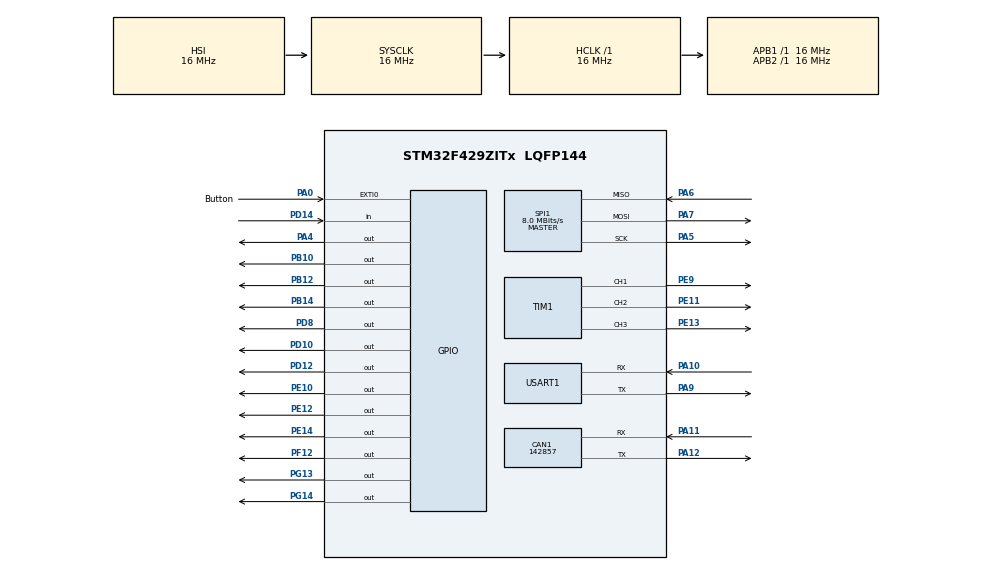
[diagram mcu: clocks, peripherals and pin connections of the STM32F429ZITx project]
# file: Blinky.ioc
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CAN1.BS1=CAN_BS1_4TQ
CAN1.BS2=CAN_BS2_2TQ
CAN1.CalculateBaudRate=142857
CAN1.CalculateTimeBit=7000
CAN1.CalculateTimeQuantum=1000.0
Mcu.Family=STM32F4
Mcu.Name=STM32F429ZITx
Mcu.Package=LQFP144
NVIC.CAN1_RX0_IRQn=true\:0\:0\:false\:false\:true\:true\:true\:true
NVIC.EXTI0_IRQn=true\:0\:0\:false\:false\:true\:true\:true\:true
NVIC.PriorityGroup=NVIC_PRIORITYGROUP_4
NVIC.TIM8_TRG_COM_TIM14_IRQn=true\:0\:0\:false\:false\:true\:true\:true\:true
PA0/WKUP.GPIO_Label=Button
PA0/WKUP.GPIO_ModeDefaultEXTI=GPIO_MODE_IT_RISING
PA0/WKUP.GPIO_PuPd=GPIO_NOPULL
PA0/WKUP.Signal=GPXTI0
PA10.Mode=Asynchronous
PA10.Signal=USART1_RX
PA11.Mode=CAN_Activate
PA11.Signal=CAN1_RX
PA12.Mode=CAN_Activate
PA12.Signal=CAN1_TX
PA4.Signal=GPIO_Output
PA5.Mode=Full_Duplex_Master
PA5.Signal=SPI1_SCK
PA6.Mode=Full_Duplex_Master
PA6.Signal=SPI1_MISO
PA7.Mode=Full_Duplex_Master
PA7.Signal=SPI1_MOSI
PA9.Mode=Asynchronous
PA9.Signal=USART1_TX
PB10.Signal=GPIO_Output
PB12.Signal=GPIO_Output
PB14.Signal=GPIO_Output
PB15.Signal=S_TIM12_CH2
PC14/OSC32_IN.Mode=LSE-External-Oscillator
PC14/OSC32_IN.Signal=RCC_OSC32_IN
PC15/OSC32_OUT.Mode=LSE-External-Oscillator
PC15/OSC32_OUT.Signal=RCC_OSC32_OUT
PD10.Signal=GPIO_Output
PD12.Signal=GPIO_Output
PD14.Signal=GPIO_Input
PD8.Signal=GPIO_Output
PE10.Signal=GPIO_Output
PE11.Signal=S_TIM1_CH2
PE12.Signal=GPIO_Output
PE13.Signal=S_TIM1_CH3
PE14.Signal=GPIO_Output
PE9.Signal=S_TIM1_CH1
PF12.Signal=GPIO_Output
PG13.Signal=GPIO_Output
PG14.Signal=GPIO_Output
PH0/OSC_IN.Mode=HSE-External-Oscillator
PH0/OSC_IN.Signal=RCC_OSC_IN
PH1/OSC_OUT.Mode=HSE-External-Oscillator
PH1/OSC_OUT.Signal=RCC_OSC_OUT
ProjectManager.HeapSize=0x200
ProjectManager.StackSize=0x400
ProjectManager.TargetToolchain=STM32CubeIDE
RCC.AHBFreq_Value=16000000
RCC.APB1Freq_Value=16000000
RCC.APB2Freq_Value=16000000
RCC.CortexFreq_Value=16000000
RCC.HSE_VALUE=25000000
RCC.HSI_VALUE=16000000
RCC.SYSCLKFreq_VALUE=16000000
RCC.VCOOutputFreq_Value=192000000
SH.S_TIM12_CH2.0=TIM12_CH2
SH.S_TIM1_CH1.0=TIM1_CH1,PWM Generation1 CH1
SH.S_TIM1_CH2.0=TIM1_CH2,PWM Generation2 CH2
SH.S_TIM1_CH3.0=TIM1_CH3,PWM Generation3 CH3
SPI1.CalculateBaudRate=8.0 MBits/s
SPI1.DataSize=SPI_DATASIZE_16BIT
SPI1.Direction=SPI_DIRECTION_2LINES
SPI1.Mode=SPI_MODE_MASTER
SPI1.VirtualType=VM_MASTER
TIM1.AutoReloadPreload=TIM_AUTORELOAD_PRELOAD_ENABLE
TIM1.Channel-PWM\ Generation1\ CH1=TIM_CHANNEL_1
TIM1.Channel-PWM\ Generation2\ CH2=TIM_CHANNEL_2
TIM1.Channel-PWM\ Generation3\ CH3=TIM_CHANNEL_3
TIM13.Period=10000-1
TIM13.Prescaler=1600-1
TIM14.Period=10000 - 1
TIM14.Prescaler=1600 -1
USART1.VirtualMode=VM_ASYNC
VP_TIM13_VS_ClockSourceINT.Mode=Enable_Timer
VP_TIM14_VS_ClockSourceINT.Mode=Enable_Timer
VP_TIM1_VS_ClockSourceINT.Mode=Internal
board=custom

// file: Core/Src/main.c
/* USER CODE BEGIN Header */
/**
  ******************************************************************************
  * @file           : main.c
  * @brief          : Main program body
  ******************************************************************************
  * @attention
  *
  * Copyright (c) 2022 STMicroelectronics.
  * All rights reserved.
  *
  * This software is licensed under terms that can be found in the LICENSE file
  * in the root directory of this software component.
  * If no LICENSE file comes with this software, it is provided AS-IS.
  *
  ******************************************************************************
  */
/* USER CODE END Header */
#include "main.h"

 CAN_HandleTypeDef hcan1;

SPI_HandleTypeDef hspi1;

TIM_HandleTypeDef htim1;
TIM_HandleTypeDef htim13;
TIM_HandleTypeDef htim14;

UART_HandleTypeDef huart1;

void SystemClock_Config(void);
static void MX_GPIO_Init(void);
static void MX_TIM1_Init(void);
static void MX_SPI1_Init(void);
static void MX_CAN1_Init(void);
static void MX_USART1_UART_Init(void);
static void MX_TIM14_Init(void);
static void MX_TIM13_Init(void);
/* USER CODE BEGIN PFP */
int flashLEDs = 1;
int buttonVal = 0;
/* USER CODE END PFP */

int main(void)
{

  /* MCU Configuration--------------------------------------------------------*/

  /* Reset of all peripherals, Initializes the Flash interface and the Systick. */
  HAL_Init();

  /* Configure the system clock */
  SystemClock_Config();

  /* Initialize all configured peripherals */
  MX_GPIO_Init();
  MX_TIM1_Init();
  MX_SPI1_Init();
  MX_CAN1_Init();
  MX_USART1_UART_Init();
  MX_TIM14_Init();
  MX_TIM13_Init();
  /* USER CODE BEGIN 2 */
  HAL_UART_Transmit(&huart1, (uint8_t *)"hello\n", strlen("hello\n"), 1000);
  char in[8] = {0};
  /* USER CODE END 2 */

  /* Infinite loop */
  /* USER CODE BEGIN WHILE */
  while (1)
  {
	 if(flashLEDs){
		 HAL_GPIO_TogglePin(GPIOG, GPIO_PIN_13);
		 //HAL_Delay(100);
		 HAL_GPIO_TogglePin(GPIOG, GPIO_PIN_14);
	 }
	 else{
		 HAL_GPIO_WritePin(GPIOG, GPIO_PIN_13, 0);
		 HAL_GPIO_WritePin(GPIOG, GPIO_PIN_14, 0);
	 }
	 buttonVal = HAL_GPIO_ReadPin(GPIOA, GPIO_PIN_0);

	 //HAL_Delay(100);

	 if(HAL_UART_Receive(&huart1, (uint8_t *)in, 8, 1000) == HAL_TIMEOUT){
		 //HAL_UART_Transmit(&huart1, (uint8_t *)"Timeout\n", strlen("Timeout\n") , 10);
	 }
	 else{
		 HAL_UART_Transmit(&huart1, (uint8_t *)in, 8 , 1);
	 }

    /* USER CODE END WHILE */

  }
}

void SystemClock_Config(void)
{
  RCC_OscInitTypeDef RCC_OscInitStruct = {0};
  RCC_ClkInitTypeDef RCC_ClkInitStruct = {0};

  /** Configure the main internal regulator output voltage
  */
  __HAL_RCC_PWR_CLK_ENABLE();
  __HAL_PWR_VOLTAGESCALING_CONFIG(PWR_REGULATOR_VOLTAGE_SCALE3);

  /** Initializes the RCC Oscillators according to the specified parameters
  * in the RCC_OscInitTypeDef structure.
  */
  RCC_OscInitStruct.OscillatorType = RCC_OSCILLATORTYPE_HSI;
  RCC_OscInitStruct.HSIState = RCC_HSI_ON;
  RCC_OscInitStruct.HSICalibrationValue = RCC_HSICALIBRATION_DEFAULT;
  RCC_OscInitStruct.PLL.PLLState = RCC_PLL_NONE;
  if (HAL_RCC_OscConfig(&RCC_OscInitStruct) != HAL_OK)
  {
    Error_Handler();
  }

  /** Initializes the CPU, AHB and APB buses clocks
  */
  RCC_ClkInitStruct.ClockType = RCC_CLOCKTYPE_HCLK|RCC_CLOCKTYPE_SYSCLK
                              |RCC_CLOCKTYPE_PCLK1|RCC_CLOCKTYPE_PCLK2;
  RCC_ClkInitStruct.SYSCLKSource = RCC_SYSCLKSOURCE_HSI;
  RCC_ClkInitStruct.AHBCLKDivider = RCC_SYSCLK_DIV1;
  RCC_ClkInitStruct.APB1CLKDivider = RCC_HCLK_DIV1;
  RCC_ClkInitStruct.APB2CLKDivider = RCC_HCLK_DIV1;

  if (HAL_RCC_ClockConfig(&RCC_ClkInitStruct, FLASH_LATENCY_0) != HAL_OK)
  {
    Error_Handler();
  }
}

static void MX_CAN1_Init(void)
{

  hcan1.Instance = CAN1;
  hcan1.Init.Prescaler = 16;
  hcan1.Init.Mode = CAN_MODE_NORMAL;
  hcan1.Init.SyncJumpWidth = CAN_SJW_1TQ;
  hcan1.Init.TimeSeg1 = CAN_BS1_4TQ;
  hcan1.Init.TimeSeg2 = CAN_BS2_2TQ;
  hcan1.Init.TimeTriggeredMode = DISABLE;
  hcan1.Init.AutoBusOff = DISABLE;
  hcan1.Init.AutoWakeUp = DISABLE;
  hcan1.Init.AutoRetransmission = DISABLE;
  hcan1.Init.ReceiveFifoLocked = DISABLE;
  hcan1.Init.TransmitFifoPriority = DISABLE;
  if (HAL_CAN_Init(&hcan1) != HAL_OK)
  {
    Error_Handler();
  }

}

static void MX_SPI1_Init(void)
{

  /* SPI1 parameter configuration*/
  hspi1.Instance = SPI1;
  hspi1.Init.Mode = SPI_MODE_MASTER;
  hspi1.Init.Direction = SPI_DIRECTION_2LINES;
  hspi1.Init.DataSize = SPI_DATASIZE_16BIT;
  hspi1.Init.CLKPolarity = SPI_POLARITY_LOW;
  hspi1.Init.CLKPhase = SPI_PHASE_1EDGE;
  hspi1.Init.NSS = SPI_NSS_SOFT;
  hspi1.Init.BaudRatePrescaler = SPI_BAUDRATEPRESCALER_2;
  hspi1.Init.FirstBit = SPI_FIRSTBIT_MSB;
  hspi1.Init.TIMode = SPI_TIMODE_DISABLE;
  hspi1.Init.CRCCalculation = SPI_CRCCALCULATION_DISABLE;
  hspi1.Init.CRCPolynomial = 10;
  if (HAL_SPI_Init(&hspi1) != HAL_OK)
  {
    Error_Handler();
  }

}

static void MX_TIM1_Init(void)
{

  TIM_ClockConfigTypeDef sClockSourceConfig = {0};
  TIM_MasterConfigTypeDef sMasterConfig = {0};
  TIM_OC_InitTypeDef sConfigOC = {0};
  TIM_BreakDeadTimeConfigTypeDef sBreakDeadTimeConfig = {0};

  htim1.Instance = TIM1;
  htim1.Init.Prescaler = 0;
  htim1.Init.CounterMode = TIM_COUNTERMODE_UP;
  htim1.Init.Period = 65535;
  htim1.Init.ClockDivision = TIM_CLOCKDIVISION_DIV1;
  htim1.Init.RepetitionCounter = 0;
  htim1.Init.AutoReloadPreload = TIM_AUTORELOAD_PRELOAD_ENABLE;
  if (HAL_TIM_Base_Init(&htim1) != HAL_OK)
  {
    Error_Handler();
  }
  sClockSourceConfig.ClockSource = TIM_CLOCKSOURCE_INTERNAL;
  if (HAL_TIM_ConfigClockSource(&htim1, &sClockSourceConfig) != HAL_OK)
  {
    Error_Handler();
  }
  if (HAL_TIM_PWM_Init(&htim1) != HAL_OK)
  {
    Error_Handler();
  }
  sMasterConfig.MasterOutputTrigger = TIM_TRGO_RESET;
  sMasterConfig.MasterSlaveMode = TIM_MASTERSLAVEMODE_DISABLE;
  if (HAL_TIMEx_MasterConfigSynchronization(&htim1, &sMasterConfig) != HAL_OK)
  {
    Error_Handler();
  }
  sConfigOC.OCMode = TIM_OCMODE_PWM1;
  sConfigOC.Pulse = 0;
  sConfigOC.OCPolarity = TIM_OCPOLARITY_HIGH;
  sConfigOC.OCNPolarity = TIM_OCNPOLARITY_HIGH;
  sConfigOC.OCFastMode = TIM_OCFAST_DISABLE;
  sConfigOC.OCIdleState = TIM_OCIDLESTATE_RESET;
  sConfigOC.OCNIdleState = TIM_OCNIDLESTATE_RESET;
  if (HAL_TIM_PWM_ConfigChannel(&htim1, &sConfigOC, TIM_CHANNEL_1) != HAL_OK)
  {
    Error_Handler();
  }
  if (HAL_TIM_PWM_ConfigChannel(&htim1, &sConfigOC, TIM_CHANNEL_2) != HAL_OK)
  {
    Error_Handler();
  }
  if (HAL_TIM_PWM_ConfigChannel(&htim1, &sConfigOC, TIM_CHANNEL_3) != HAL_OK)
  {
    Error_Handler();
  }
  sBreakDeadTimeConfig.OffStateRunMode = TIM_OSSR_DISABLE;
  sBreakDeadTimeConfig.OffStateIDLEMode = TIM_OSSI_DISABLE;
  sBreakDeadTimeConfig.LockLevel = TIM_LOCKLEVEL_OFF;
  sBreakDeadTimeConfig.DeadTime = 0;
  sBreakDeadTimeConfig.BreakState = TIM_BREAK_DISABLE;
  sBreakDeadTimeConfig.BreakPolarity = TIM_BREAKPOLARITY_HIGH;
  sBreakDeadTimeConfig.AutomaticOutput = TIM_AUTOMATICOUTPUT_DISABLE;
  if (HAL_TIMEx_ConfigBreakDeadTime(&htim1, &sBreakDeadTimeConfig) != HAL_OK)
  {
    Error_Handler();
  }
  HAL_TIM_MspPostInit(&htim1);

}

static void MX_TIM13_Init(void)
{

  htim13.Instance = TIM13;
  htim13.Init.Prescaler = 1600-1;
  htim13.Init.CounterMode = TIM_COUNTERMODE_UP;
  htim13.Init.Period = 10000-1;
  htim13.Init.ClockDivision = TIM_CLOCKDIVISION_DIV1;
  htim13.Init.AutoReloadPreload = TIM_AUTORELOAD_PRELOAD_DISABLE;
  if (HAL_TIM_Base_Init(&htim13) != HAL_OK)
  {
    Error_Handler();
  }

}

static void MX_TIM14_Init(void)
{

  htim14.Instance = TIM14;
  htim14.Init.Prescaler = 1600 -1;
  htim14.Init.CounterMode = TIM_COUNTERMODE_UP;
  htim14.Init.Period = 10000 - 1;
  htim14.Init.ClockDivision = TIM_CLOCKDIVISION_DIV1;
  htim14.Init.AutoReloadPreload = TIM_AUTORELOAD_PRELOAD_DISABLE;
  if (HAL_TIM_Base_Init(&htim14) != HAL_OK)
  {
    Error_Handler();
  }

}

static void MX_USART1_UART_Init(void)
{

  huart1.Instance = USART1;
  huart1.Init.BaudRate = 115200;
  huart1.Init.WordLength = UART_WORDLENGTH_8B;
  huart1.Init.StopBits = UART_STOPBITS_1;
  huart1.Init.Parity = UART_PARITY_NONE;
  huart1.Init.Mode = UART_MODE_TX_RX;
  huart1.Init.HwFlowCtl = UART_HWCONTROL_NONE;
  huart1.Init.OverSampling = UART_OVERSAMPLING_16;
  if (HAL_UART_Init(&huart1) != HAL_OK)
  {
    Error_Handler();
  }

}

static void MX_GPIO_Init(void)
{
  GPIO_InitTypeDef GPIO_InitStruct = {0};

  /* GPIO Ports Clock Enable */
  __HAL_RCC_GPIOC_CLK_ENABLE();
  __HAL_RCC_GPIOH_CLK_ENABLE();
  __HAL_RCC_GPIOA_CLK_ENABLE();
  __HAL_RCC_GPIOF_CLK_ENABLE();
  __HAL_RCC_GPIOE_CLK_ENABLE();
  __HAL_RCC_GPIOB_CLK_ENABLE();
  __HAL_RCC_GPIOD_CLK_ENABLE();
  __HAL_RCC_GPIOG_CLK_ENABLE();

  /*Configure GPIO pin Output Level */
  HAL_GPIO_WritePin(GPIOA, GPIO_PIN_4, GPIO_PIN_RESET);

  /*Configure GPIO pin Output Level */
  HAL_GPIO_WritePin(GPIOF, GPIO_PIN_12, GPIO_PIN_RESET);

  /*Configure GPIO pin Output Level */
  HAL_GPIO_WritePin(GPIOE, GPIO_PIN_10|GPIO_PIN_12|GPIO_PIN_14, GPIO_PIN_RESET);

  /*Configure GPIO pin Output Level */
  HAL_GPIO_WritePin(GPIOB, GPIO_PIN_10|GPIO_PIN_12|GPIO_PIN_14, GPIO_PIN_RESET);

  /*Configure GPIO pin Output Level */
  HAL_GPIO_WritePin(GPIOD, GPIO_PIN_8|GPIO_PIN_10|GPIO_PIN_12, GPIO_PIN_RESET);

  /*Configure GPIO pin Output Level */
  HAL_GPIO_WritePin(GPIOG, GPIO_PIN_13|GPIO_PIN_14, GPIO_PIN_RESET);

  /*Configure GPIO pin : Button_Pin */
  GPIO_InitStruct.Pin = Button_Pin;
  GPIO_InitStruct.Mode = GPIO_MODE_IT_RISING;
  GPIO_InitStruct.Pull = GPIO_NOPULL;
  HAL_GPIO_Init(Button_GPIO_Port, &GPIO_InitStruct);

  /*Configure GPIO pin : PA4 */
  GPIO_InitStruct.Pin = GPIO_PIN_4;
  GPIO_InitStruct.Mode = GPIO_MODE_OUTPUT_PP;
  GPIO_InitStruct.Pull = GPIO_NOPULL;
  GPIO_InitStruct.Speed = GPIO_SPEED_FREQ_LOW;
  HAL_GPIO_Init(GPIOA, &GPIO_InitStruct);

  /*Configure GPIO pin : PF12 */
  GPIO_InitStruct.Pin = GPIO_PIN_12;
  GPIO_InitStruct.Mode = GPIO_MODE_OUTPUT_PP;
  GPIO_InitStruct.Pull = GPIO_NOPULL;
  GPIO_InitStruct.Speed = GPIO_SPEED_FREQ_LOW;
  HAL_GPIO_Init(GPIOF, &GPIO_InitStruct);

  /*Configure GPIO pins : PE10 PE12 PE14 */
  GPIO_InitStruct.Pin = GPIO_PIN_10|GPIO_PIN_12|GPIO_PIN_14;
  GPIO_InitStruct.Mode = GPIO_MODE_OUTPUT_PP;
  GPIO_InitStruct.Pull = GPIO_NOPULL;
  GPIO_InitStruct.Speed = GPIO_SPEED_FREQ_LOW;
  HAL_GPIO_Init(GPIOE, &GPIO_InitStruct);

  /*Configure GPIO pins : PB10 PB12 PB14 */
  GPIO_InitStruct.Pin = GPIO_PIN_10|GPIO_PIN_12|GPIO_PIN_14;
  GPIO_InitStruct.Mode = GPIO_MODE_OUTPUT_PP;
  GPIO_InitStruct.Pull = GPIO_NOPULL;
  GPIO_InitStruct.Speed = GPIO_SPEED_FREQ_LOW;
  HAL_GPIO_Init(GPIOB, &GPIO_InitStruct);

  /*Configure GPIO pin : PB15 */
  GPIO_InitStruct.Pin = GPIO_PIN_15;
  GPIO_InitStruct.Mode = GPIO_MODE_AF_PP;
  GPIO_InitStruct.Pull = GPIO_NOPULL;
  GPIO_InitStruct.Speed = GPIO_SPEED_FREQ_LOW;
  GPIO_InitStruct.Alternate = GPIO_AF9_TIM12;
  HAL_GPIO_Init(GPIOB, &GPIO_InitStruct);

  /*Configure GPIO pins : PD8 PD10 PD12 */
  GPIO_InitStruct.Pin = GPIO_PIN_8|GPIO_PIN_10|GPIO_PIN_12;
  GPIO_InitStruct.Mode = GPIO_MODE_OUTPUT_PP;
  GPIO_InitStruct.Pull = GPIO_NOPULL;
  GPIO_InitStruct.Speed = GPIO_SPEED_FREQ_LOW;
  HAL_GPIO_Init(GPIOD, &GPIO_InitStruct);

  /*Configure GPIO pin : PD14 */
  GPIO_InitStruct.Pin = GPIO_PIN_14;
  GPIO_InitStruct.Mode = GPIO_MODE_INPUT;
  GPIO_InitStruct.Pull = GPIO_NOPULL;
  HAL_GPIO_Init(GPIOD, &GPIO_InitStruct);

  /*Configure GPIO pins : PG13 PG14 */
  GPIO_InitStruct.Pin = GPIO_PIN_13|GPIO_PIN_14;
  GPIO_InitStruct.Mode = GPIO_MODE_OUTPUT_PP;
  GPIO_InitStruct.Pull = GPIO_NOPULL;
  GPIO_InitStruct.Speed = GPIO_SPEED_FREQ_LOW;
  HAL_GPIO_Init(GPIOG, &GPIO_InitStruct);

  /* EXTI interrupt init*/
  HAL_NVIC_SetPriority(EXTI0_IRQn, 0, 0);
  HAL_NVIC_EnableIRQ(EXTI0_IRQn);

}

void Error_Handler(void)
{
  __disable_irq();
  while (1)
  {
  }
}
